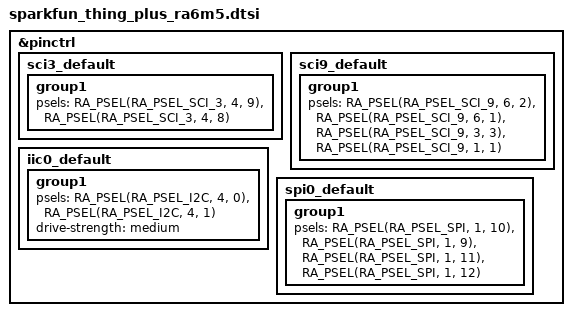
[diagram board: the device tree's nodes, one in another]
/*
 * Copyright (c) 2025 Ian Morris
 * SPDX-License-Identifier: Apache-2.0
 */

&pinctrl {
	sci3_default: sci3_default {
		group1 {
			/* txd rxd */
			psels = <RA_PSEL(RA_PSEL_SCI_3, 4, 9)>,
			<RA_PSEL(RA_PSEL_SCI_3, 4, 8)>;
		};
	};

	sci9_default: sci9_default {
		group1 {
			/* txd, rxd, rts, cts*/
			psels = <RA_PSEL(RA_PSEL_SCI_9, 6, 2)>,
			<RA_PSEL(RA_PSEL_SCI_9, 6, 1)>,
			<RA_PSEL(RA_PSEL_SCI_9, 3, 3)>,
			<RA_PSEL(RA_PSEL_SCI_9, 1, 1)>;
		};
	};

	iic0_default: iic0_default {
		group1 {
			/* SCL0 SDA0 */
			psels = <RA_PSEL(RA_PSEL_I2C, 4, 0)>,
			<RA_PSEL(RA_PSEL_I2C, 4, 1)>;
			drive-strength = "medium";
		};
	};

	spi0_default: spi0_default {
		group1 {
			/* MISO MOSI RSPCK SSL */
			psels = <RA_PSEL(RA_PSEL_SPI, 1, 10)>,
			<RA_PSEL(RA_PSEL_SPI, 1, 9)>,
			<RA_PSEL(RA_PSEL_SPI, 1, 11)>,
			<RA_PSEL(RA_PSEL_SPI, 1, 12)>;
		};
	};
};
